# S32K324_M7 register map
Vendor: NXP Semiconductors; File version: 1.1
CPU: CM7 r0p1, little endian, MPU, FPU, VTOR, 4 interrupt priority bits
Registers are 32-bit, read-write, reset 0x0 unless marked. A register's access mark holds for its fields unless they carry their own. Offsets are from the block's base; [hi:lo] are bit positions.

## MC_RGM
Base 0x4028C000
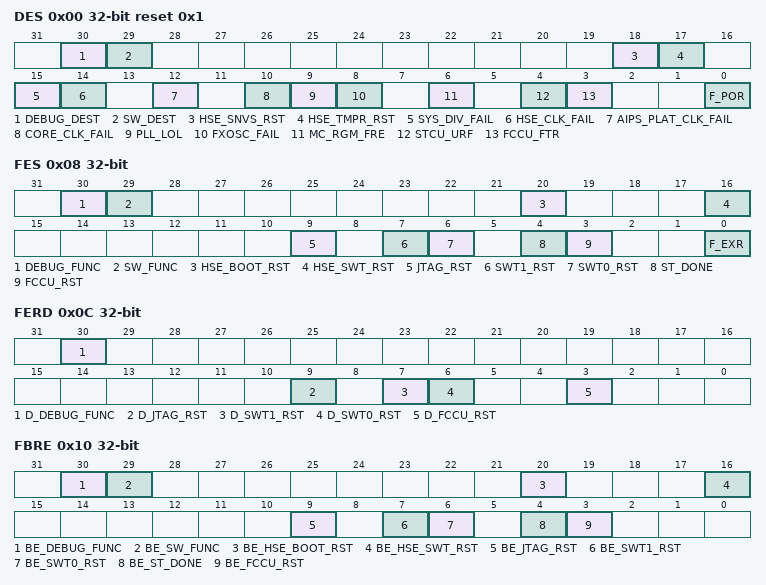
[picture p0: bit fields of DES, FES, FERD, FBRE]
0x00 DES reset 0x1 write-1-clears — Destructive Event Status Register
  [30] DEBUG_DEST write-1-clears — Flag for 'Destructive' Reset DEBUG_DEST
    0=NO_DEST_RESET ('Destructive' reset event DEBUG_DEST has not occurred since either the last clear or the last power-on reset assertion.); 1=DEST_RESET ('Destructive' reset event DEBUG_DEST has occurred.)
  [29] SW_DEST write-1-clears — Flag for 'Destructive' Reset SW_DEST
    0=NO_DEST_RESET ('Destructive' reset event SW_DEST has not occurred since either the last clear or the last power-on reset assertion.); 1=DEST_RESET ('Destructive' reset event SW_DEST has occurred.)
  [18] HSE_SNVS_RST write-1-clears — Flag for 'Destructive' Reset HSE_SNVS_RST
    0=NO_DEST_RESET ('Destructive' reset event HSE_SNVS_RST has not occurred since either the last clear or the last power-on reset assertion.); 1=DEST_RESET ('Destructive' reset event HSE_SNVS_RST has occurred.)
  [17] HSE_TMPR_RST write-1-clears — Flag for 'Destructive' Reset HSE_TMPR_RST
    0=NO_DEST_RESET ('Destructive' reset event HSE_TMPR_RST has not occurred since either the last clear or the last power-on reset assertion.); 1=DEST_RESET ('Destructive' reset event HSE_TMPR_RST has occurred.)
  [15] SYS_DIV_FAIL write-1-clears — Flag for 'Destructive' Reset SYS_DIV_FAIL
    0=NO_DEST_RESET ('Destructive' reset event SYS_DIV_FAIL has not occurred since either the last clear or the last power-on reset assertion.); 1=DEST_RESET ('Destructive' reset event SYS_DIV_FAIL has occurred.)
  [14] HSE_CLK_FAIL write-1-clears — Flag for 'Destructive' Reset HSE_CLK_FAIL
    0=NO_DEST_RESET ('Destructive' reset event HSE_CLK_FAIL has not occurred since either the last clear or the last power-on reset assertion.); 1=DEST_RESET ('Destructive' reset event HSE_CLK_FAIL has occurred.)
  [12] AIPS_PLAT_CLK_FAIL write-1-clears — Flag for 'Destructive' Reset AIPS_PLAT_CLK_FAIL
    0=NO_DEST_RESET ('Destructive' reset event AIPS_PLAT_CLK_FAIL has not occurred since either the last clear or the last power-on reset assertion.); 1=DEST_RESET ('Destructive' reset event AIPS_PLAT_CLK_FAIL has occurred.)
  [10] CORE_CLK_FAIL write-1-clears — Flag for 'Destructive' Reset CORE_CLK_FAIL
    0=NO_DEST_RESET ('Destructive' reset event CORE_CLK_FAIL has not occurred since either the last clear or the last power-on reset assertion.); 1=DEST_RESET ('Destructive' reset event CORE_CLK_FAIL has occurred.)
  [9] PLL_LOL write-1-clears — Flag for 'Destructive' Reset PLL_LOL
    0=NO_DEST_RESET ('Destructive' reset event PLL_LOL has not occurred since either the last clear or the last power-on reset assertion.); 1=DEST_RESET ('Destructive' reset event PLL_LOL has occurred.)
  [8] FXOSC_FAIL write-1-clears — Flag for 'Destructive' Reset FXOSC_FAIL
    0=NO_DEST_RESET ('Destructive' reset event FXOSC_FAIL has not occurred since either the last clear or the last power-on reset assertion.); 1=DEST_RESET ('Destructive' reset event FXOSC_FAIL has occurred.)
  [6] MC_RGM_FRE write-1-clears — Flag for 'Destructive' Reset MC_RGM_FRE
    0=NO_DEST_RESET ('Destructive' reset event MC_RGM_FRE has not occurred since either the last clear or the last power-on reset assertion.); 1=DEST_RESET ('Destructive' reset event MC_RGM_FRE has occurred.)
  [4] STCU_URF write-1-clears — Flag for 'Destructive' Reset STCU_URF
    0=NO_DEST_RESET ('Destructive' reset event STCU_URF has not occurred since either the last clear or the last power-on reset assertion.); 1=DEST_RESET ('Destructive' reset event STCU_URF has occurred.)
  [3] FCCU_FTR write-1-clears — Flag for 'Destructive' Reset FCCU_FTR
    0=NO_DEST_RESET ('Destructive' reset event FCCU_FTR has not occurred since either the last clear or the last power-on reset assertion.); 1=DEST_RESET ('Destructive' reset event FCCU_FTR has occurred.)
  [0] F_POR write-1-clears — Flag for power-on reset
    0=NO_POWER_ON (No power-on event has occurred since the last clear.); 1=POWER_ON (A power-on event has occurred.)
0x08 FES write-1-clears — Functional /External Reset Status Register
  [30] DEBUG_FUNC write-1-clears — Flag for 'Functional' Reset DEBUG_FUNC
    0=NO_FUNC_RESET ('Functional' reset event DEBUG_FUNC has not occurred since either the last clear or the last power-on reset assertion.); 1=FUNC_RESET ('Functional' reset event DEBUG_FUNC has occurred.)
  [29] SW_FUNC write-1-clears — Flag for 'Functional' Reset SW_FUNC
    0=NO_FUNC_RESET ('Functional' reset event SW_FUNC has not occurred since either the last clear or the last power-on reset assertion.); 1=FUNC_RESET ('Functional' reset event SW_FUNC has occurred.)
  [20] HSE_BOOT_RST write-1-clears — Flag for 'Functional' Reset HSE_BOOT_RST
    0=NO_FUNC_RESET ('Functional' reset event HSE_BOOT_RST has not occurred since either the last clear or the last power-on reset assertion.); 1=FUNC_RESET ('Functional' reset event HSE_BOOT_RST has occurred.)
  [16] HSE_SWT_RST write-1-clears — Flag for 'Functional' Reset HSE_SWT_RST
    0=NO_FUNC_RESET ('Functional' reset event HSE_SWT_RST has not occurred since either the last clear or the last power-on reset assertion.); 1=FUNC_RESET ('Functional' reset event HSE_SWT_RST has occurred.)
  [9] JTAG_RST write-1-clears — Flag for 'Functional' Reset JTAG_RST
    0=NO_FUNC_RESET ('Functional' reset event JTAG_RST has not occurred since either the last clear or the last power-on reset assertion.); 1=FUNC_RESET ('Functional' reset event JTAG_RST has occurred.)
  [7] SWT1_RST write-1-clears — Flag for 'Functional' Reset SWT1_RST
    0=NO_FUNC_RESET ('Functional' reset event SWT1_RST has not occurred since either the last clear or the last power-on reset assertion.); 1=FUNC_RESET ('Functional' reset event SWT1_RST has occurred.)
  [6] SWT0_RST write-1-clears — Flag for 'Functional' Reset SWT0_RST
    0=NO_FUNC_RESET ('Functional' reset event SWT0_RST has not occurred since either the last clear or the last power-on reset assertion.); 1=FUNC_RESET ('Functional' reset event SWT0_RST has occurred.)
  [4] ST_DONE write-1-clears — Flag for 'Functional' Reset ST_DONE
    0=NO_FUNC_RESET ('Functional' reset event ST_DONE has not occurred since either the last clear or the last power-on reset assertion.); 1=FUNC_RESET ('Functional' reset event ST_DONE has occurred.)
  [3] FCCU_RST write-1-clears — Flag for 'Functional' Reset FCCU_RST
    0=NO_FUNC_RESET ('Functional' reset event FCCU_RST has not occurred since either the last clear or the last power-on reset assertion.); 1=FUNC_RESET ('Functional' reset event FCCU_RST has occurred.)
  [0] F_EXR write-1-clears — Flag for External Reset
    0=NO_EXT_RESET (No external reset event has occurred since either the last clear or the last power-on reset assertion.); 1=EXT_RESET (An external reset event has occurred.)
0x0C FERD rw-once — Functional Event Reset Disable Register
  [30] D_DEBUG_FUNC — DEBUG_FUNC Disable Control
    0=RESET (Functional reset event DEBUG_FUNC triggers a reset sequence.); 1=INTERRUPT (Functional reset event DEBUG_FUNC generates an interrupt request.)
  [9] D_JTAG_RST — JTAG_RST Disable Control
    0=RESET (Functional reset event JTAG_RST triggers a reset sequence.); 1=INTERRUPT (Functional reset event JTAG_RST generates an interrupt request.)
  [7] D_SWT1_RST — SWT1_RST Disable Control
    0=RESET (Functional reset event SWT1_RST triggers a reset sequence.); 1=INTERRUPT (Functional reset event SWT1_RST generates an interrupt request.)
  [6] D_SWT0_RST — SWT0_RST Disable Control
    0=RESET (Functional reset event SWT0_RST triggers a reset sequence.); 1=INTERRUPT (Functional reset event SWT0_RST generates an interrupt request.)
  [3] D_FCCU_RST — FCCU_RST Disable Control
    0=RESET (Functional reset event FCCU_RST triggers a reset sequence.); 1=INTERRUPT (Functional reset event FCCU_RST generates an interrupt request.)
0x10 FBRE — Functional Bidirectional Reset Enable Register
  [30] BE_DEBUG_FUNC ro — Bidirectional Reset Enables for 'Functional' Reset DEBUG_FUNC
    0=EXT_PIN_ASSERTED (External reset pin is asserted on a 'Functional' reset DEBUG_FUNC event if the reset is enabled.); 1=EXT_PIN_NOT_ASSERTED (External reset pin is not asserted on a 'functional' reset DEBUG_FUNC event.)
  [29] BE_SW_FUNC ro — Bidirectional Reset Enables for 'Functional' Reset SW_FUNC
    0=EXT_PIN_ASSERTED (External reset pin is asserted on a 'Functional' reset SW_FUNC event if the reset is enabled.); 1=EXT_PIN_NOT_ASSERTED (External reset pin is not asserted on a 'functional' reset SW_FUNC event.)
  [20] BE_HSE_BOOT_RST ro — Bidirectional Reset Enables for 'Functional' Reset HSE_BOOT_RST
    0=EXT_PIN_ASSERTED (External reset pin is asserted on a 'Functional' reset HSE_BOOT_RST event if the reset is enabled.); 1=EXT_PIN_NOT_ASSERTED (External reset pin is not asserted on a 'functional' reset HSE_BOOT_RST event.)
  [16] BE_HSE_SWT_RST ro — Bidirectional Reset Enables for 'Functional' Reset HSE_SWT_RST
    0=EXT_PIN_ASSERTED (External reset pin is asserted on a 'Functional' reset HSE_SWT_RST event if the reset is enabled.); 1=EXT_PIN_NOT_ASSERTED (External reset pin is not asserted on a 'functional' reset HSE_SWT_RST event.)
  [9] BE_JTAG_RST ro — Bidirectional Reset Enables for 'Functional' Reset JTAG_RST
    0=EXT_PIN_ASSERTED (External reset pin is asserted on a 'Functional' reset JTAG_RST event if the reset is enabled.); 1=EXT_PIN_NOT_ASSERTED (External reset pin is not asserted on a 'functional' reset JTAG_RST event.)
  [7] BE_SWT1_RST ro — Bidirectional Reset Enables for 'Functional' Reset SWT1_RST
    0=EXT_PIN_ASSERTED (External reset pin is asserted on a 'Functional' reset SWT1_RST event if the reset is enabled.); 1=EXT_PIN_NOT_ASSERTED (External reset pin is not asserted on a 'functional' reset SWT1_RST event.)
  [6] BE_SWT0_RST ro — Bidirectional Reset Enables for 'Functional' Reset SWT0_RST
    0=EXT_PIN_ASSERTED (External reset pin is asserted on a 'Functional' reset SWT0_RST event if the reset is enabled.); 1=EXT_PIN_NOT_ASSERTED (External reset pin is not asserted on a 'functional' reset SWT0_RST event.)
  [4] BE_ST_DONE — Bidirectional Reset Enables for 'Functional' Reset ST_DONE
    0=EXT_PIN_ASSERTED (External reset pin is asserted on a 'Functional' reset ST_DONE event if the reset is enabled.); 1=EXT_PIN_NOT_ASSERTED (External reset pin is not asserted on a 'functional' reset ST_DONE event.)
  [3] BE_FCCU_RST ro — Bidirectional Reset Enables for 'Functional' Reset FCCU_RST
    0=EXT_PIN_ASSERTED (External reset pin is asserted on a 'Functional' reset FCCU_RST event if the reset is enabled.); 1=EXT_PIN_NOT_ASSERTED (External reset pin is not asserted on a 'functional' reset FCCU_RST event.)
0x14 FREC write-1-clears — Functional Reset Escalation Counter Register
  [3:0] FREC write-1-clears — Functional' Reset Escalation Counter
0x18 FRET reset 0xF — Functional Reset Escalation Threshold Register
  [3:0] FRET — 'Functional' Reset Escalation Threshold
0x1C DRET — Destructive Reset Escalation Threshold Register
  [3:0] DRET — 'Destructive' Reset Escalation Threshold
0x20 ERCTRL — External Reset Control Register
  [0] ERASSERT
    0=NO_CHANGE; 1=EXT_RESET_ASSERTED (External reset is asserted)
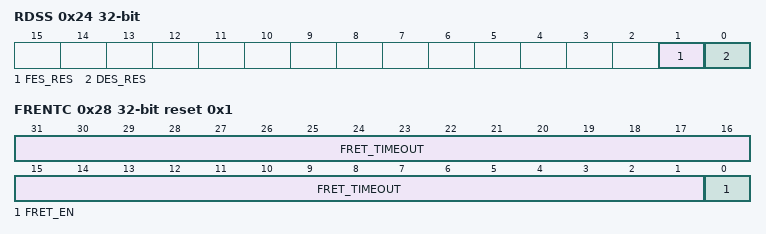
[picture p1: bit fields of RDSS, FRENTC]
0x24 RDSS write-1-clears — Reset During Standby Status Register
  [1] FES_RES write-1-clears
    0=NO_FUNC_RESET (No functional reset event occurred during standby mode.); 1=FUNC_RESET (Functional reset event occurred during standby mode.)
  [0] DES_RES write-1-clears
    0=NO_DEST_RESET (No destructive reset event occurred during standby mode.); 1=DEST_RESET (Destructive reset event occurred during standby mode.)
0x28 FRENTC reset 0x1 — Functional Reset Entry Timeout Control Register
  [31:1] FRET_TIMEOUT — Functional Reset Entry Timer Value
  [0] FRET_EN — Functional Reset Entry Timer Enable/Disable
    0=DISABLE (Functional reset entry timer is disabled.); 1=ENABLE (Functional reset entry timer is enabled)
0x2C LPDEBUG ro — Low Power Debug Control Register
  [0] LP_DBG_EN — Low-Power Debug Enable/Disable Control
    0=DISABLE (Low-power debug disabled); 1=ENABLE (Debug data collection enabled before entering low-power debug)
